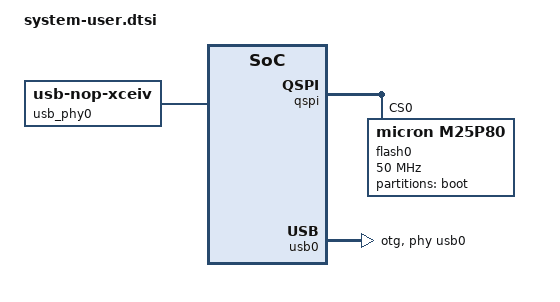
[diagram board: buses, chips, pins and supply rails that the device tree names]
/include/ "system-conf.dtsi"
/include/ "port-config.dtsi"
/ {

   xlnk {
      compatible = "xlnx,xlnk-1.0";
   };

};


&amba_pl {
   // Remove definitions auto-generated by device tree generator
   /delete-node/interrupt-controller@41800000; // axi_intc_0
};

&amba {
    axi_intc_0: axi-interrupt-ctrl {
        #interrupt-cells = <2>;
        compatible = "xlnx,axi-intc-4.1", "xlnx,xps-intc-1.00.a";
        interrupt-controller;
        reg = <0x41800000 0x1000>;
        xlnx,kind-of-intr = <0x0>;
        xlnx,num-intr-inputs = <0x20>;
        interrupt-parent = <&intc>;
        // connected at PS interrupt offset [1] (29+1=30) 
        interrupts = <0 30 4>;
    };

    zyxclmm_drm {
        compatible = "xlnx,zocl";
        status = "okay";
        interrupt-parent = <&axi_intc_0>;
        interrupts = <0  4>, <1  4>, <2  4>, <3  4>,
                 <4  4>, <5  4>, <6  4>, <7  4>,
                 <8  4>, <9  4>, <10 4>, <11 4>,
                 <12 4>, <13 4>, <14 4>, <15 4>,
                 <16 4>, <17 4>, <18 4>, <19 4>,
                 <20 4>, <21 4>, <22 4>, <23 4>,
                 <24 4>, <25 4>, <26 4>, <27 4>,
                 <28 4>, <29 4>, <30 4>, <31 4>;
    };
};


/* QSPI addresses are defined with petalinux-config, but here they are overwritten so that one can program the flash internally */
&qspi {
    #address-cells = <1>;
    #size-cells = <0>;
    flash0: flash@0 {
        compatible = "micron,m25p80";
        reg = <0x0>;
        #address-cells = <1>;
        #size-cells = <1>;
        spi-max-frequency = <50000000>;
        partition@0 {
            label = "boot";
            reg = <0x00000000 0x00ff0000>;
        };
    };
};

/ {
    usb_phy0:usb_phy@0 {
        compatible="usb-nop-xceiv";
        #phy-cells = <0>;
    };
};


&usb0 {
    dr_mode = "otg";
    usb-phy = <&usb0>;
};
